# STM32H7R register map
File version: 1.3
CPU: CM7 r0p1, little endian, MPU, FPU, 4 interrupt priority bits
Registers are 32-bit, read-write, reset 0x0 unless marked. A register's access mark holds for its fields unless they carry their own. Offsets are from the block's base; [hi:lo] are bit positions; {n}, {i} and the like mark numbered series.

## RAMCFG — RAMs configuration controller
Base 0x58027000
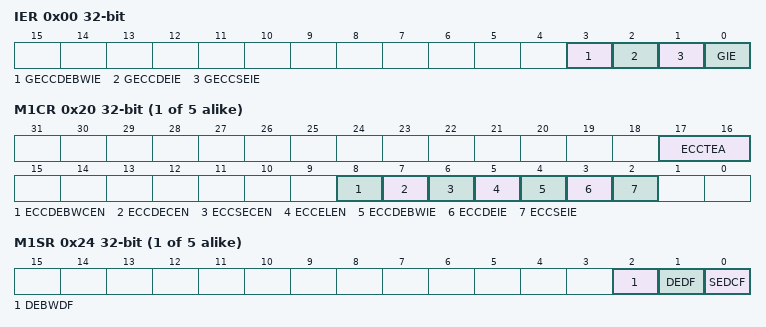
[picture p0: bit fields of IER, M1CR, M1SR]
0x00 IER — RAMECC interrupt enable register
  [3] GECCDEBWIE — Global ECC double error on byte write (BW) interrupt enable When GECCDEBWIE bit is set to 1, an interrupt is generated when an ECC double detection error occurs during a byte write operation to RAM (incomplete word write).
  [2] GECCDEIE — Global ECC double error interrupt enable When GECCDEIE bit is set to 1, an interrupt is generated when an ECC double detection error occurs during a read operation from RAM.
  [1] GECCSEIE — Global ECC single error interrupt enable When GECCSEIE bit is set to 1, an interrupt is generated when an ECC single error occurs during a read operation from RAM.
  [0] GIE — Global interrupt enable When GIE bit is set to 1, an interrupt is generated when an enabled global ECC error (GECCDEBWIE, GECCDEIE or GECCSEIE) occurs.
{0x0+0x20*i} M{i}CR (i=1..5) — RAMECC monitor {i} configuration register
  [17:16] ECCTEA — ECC Test ECC access
  [8] ECCDEBWCEN — ECC double error on byte write (BW) counter enable When ECCDEBWCEN bit is set to 1, the occurrence counter is incremented when an ECC double detection error occurs during a byte write operation to RAM.
  [7] ECCDECEN — ECC double error counter enable When ECCDECEN bit is set to 1, the occurrence counter is incremented when an ECC double detection error occurs during a read operation from RAM.
  [6] ECCSECEN — ECC single error counter enable When ECCSECEN bit is set to 1, the occurrence counter is incremented when an ECC single error occurs during a read operation from RAM.
  [5] ECCELEN — ECC error latching enable When ECCELEN bit is set to 1, if an ECC error occurs (both for single error correction or double detection) during a read operation, the context (address, data and ECC code) that generated the error are latched to their respective registers.
  [4] ECCDEBWIE — ECC double error on byte write (BW) interrupt enable When ECCDEBWIE bit is set to 1, monitor x generates an interrupt when an ECC double detection error occurs during a byte write operation to RAM.
  [3] ECCDEIE — ECC double error interrupt enable When ECCDEIE bit is set to 1, monitor x generates an interrupt when an ECC double detection error occurs during a read operation from RAM.
  [2] ECCSEIE — ECC single error interrupt enable When ECCSEIE bit is set to 1, monitor x generates an interrupt when an ECC single error occurs during a read operation from RAM.
{0x4+0x20*i} M{i}SR (i=1..5) — RAMECC monitor {i} status register
  [2] DEBWDF — ECC double error on byte write (BW) detected flag This bit is set by hardware. It is cleared by software by writing a 0
  [1] DEDF — ECC double error detected flag This bit is set by hardware. It is cleared by software by writing a 0
  [0] SEDCF — ECC single error detected and corrected flag This bit is set by hardware. It is cleared by software by writing a 0
{0x8+0x20*i} M{i}FAR ro (i=1..5) — RAMECC monitor {i} failing address register
  [31:0] FADD — ECC error failing address When an ECC error occurs the FADD bitfield contains the address that generated the ECC error.
{0xC+0x20*i} M{i}FDRL ro (i=1..5) — RAMECC monitor {i} failing data low register
  [31:0] FDATAL — Failing data low When an ECC error occurs the FDATAL bitfield contains the LSB part of the data that generated the error. For 32-bit word SRAM, this bitfield contains the full memory word that generated the error.
{0x10+0x20*i} M{i}FDRH ro (i=1..5) — RAMECC monitor {i} failing data high register
  [31:0] FDATAH — Failing data high (64-bit memory) When an ECC error occurs the FDATAH bitfield contains the MSB part of the data that generated the error.
{0x14+0x20*i} M{i}FECR ro (i=1..5) — RAMECC monitor {i} failing ECC error code register
  [31:0] FEC — Failing error code When an ECC error occurs the FEC bitfield contains the ECC failing code that generated the error.
